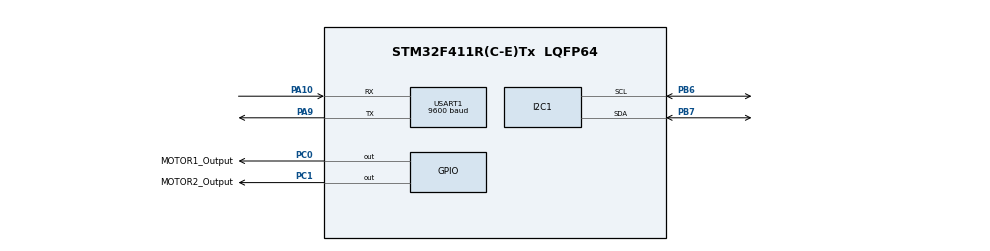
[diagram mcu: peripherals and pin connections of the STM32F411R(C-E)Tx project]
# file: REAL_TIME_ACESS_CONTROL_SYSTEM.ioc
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Mcu.Family=STM32F4
Mcu.Name=STM32F411R(C-E)Tx
Mcu.Package=LQFP64
NVIC.PriorityGroup=NVIC_PRIORITYGROUP_4
NVIC.RTC_Alarm_IRQn=true\:0\:0\:false\:false\:true\:true\:true\:true
NVIC.USART1_IRQn=true\:0\:0\:false\:false\:true\:true\:true\:true
PA10.Mode=Asynchronous
PA10.Signal=USART1_RX
PA9.Mode=Asynchronous
PA9.Signal=USART1_TX
PB6.Mode=I2C
PB6.Signal=I2C1_SCL
PB7.Mode=I2C
PB7.Signal=I2C1_SDA
PC0.GPIO_Label=MOTOR1_Output
PC0.Signal=GPIO_Output
PC1.GPIO_Label=MOTOR2_Output
PC1.Signal=GPIO_Output
ProjectManager.HeapSize=0x200
ProjectManager.StackSize=0x400
ProjectManager.TargetToolchain=STM32CubeIDE
RCC.AHBFreq_Value=16000000
RCC.APB1Freq_Value=16000000
RCC.APB2Freq_Value=16000000
RCC.CortexFreq_Value=16000000
RCC.HSE_VALUE=25000000
RCC.HSI_VALUE=16000000
RCC.LSE_VALUE=32768
RCC.SYSCLKFreq_VALUE=16000000
RCC.VCOOutputFreq_Value=192000000
RTC.Alarm=RTC_ALARM_A
RTC.Date=27
RTC.Format=RTC_FORMAT_BIN
RTC.Hours=9
RTC.Minutes=59
RTC.Month=RTC_MONTH_DECEMBER
RTC.Seconds=45
RTC.Seconds_A=10
RTC.WeekDay=RTC_WEEKDAY_TUESDAY
RTC.Year=22
USART1.BaudRate=9600
USART1.VirtualMode=VM_ASYNC
VP_RTC_VS_RTC_Activate.Mode=RTC_Enabled
VP_RTC_VS_RTC_Alarm_A_Intern.Mode=Alarm A
VP_RTC_VS_RTC_Calendar.Mode=RTC_Calendar
board=custom

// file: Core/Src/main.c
/* USER CODE BEGIN Header */
/**
  **********
  * @file           : main.c
  * @brief          : Main program body
  **********
  * @attention
  *
  * Copyright (c) 2022 STMicroelectronics.
  * All rights reserved.
  *
  * This software is licensed under terms that can be found in the LICENSE file
  * in the root directory of this software component.
  * If no LICENSE file comes with this software, it is provided AS-IS.
  *
  **********
  */
/* USER CODE END Header */
#include<stdio.h>
#include "main.h"
#include<string.h>
#include"lcd.h"
#include"RTC.h"

I2C_HandleTypeDef hi2c1;

RTC_HandleTypeDef hrtc;

UART_HandleTypeDef huart1;

RTC_HandleTypeDef hrtc;
RTC_TimeTypeDef sTime;
RTC_DateTypeDef sDate;
/* USER CODE BEGIN PV */
void MOTOR_Init(void);
void Rfid_Init(void);
/* USER CODE END PV */

void SystemClock_Config(void);
static void MX_GPIO_Init(void);
static void MX_I2C1_Init(void);
static void MX_RTC_Init(void);
static void MX_USART1_UART_Init(void);
/* USER CODE BEGIN PFP */
#define TRUE 1
#define FALSE 0
/* USER CODE END PFP */

/* USER CODE BEGIN 0 */
char *USER_DATA="Sankalp!";
uint8_t recvd_data;
	uint8_t data_buf[50];
	uint8_t count=0;
	uint8_t rec_comp_data=FALSE;
	char str[20];
	char *buffer[15];
/* USER CODE END 0 */

int main(void)
{

  /* MCU Configuration--------------------------------------------------------*/

  /* Reset of all peripherals, Initializes the Flash interface and the Systick. */
  HAL_Init();
  LCD_init();
//  RTC_init();

  /* Configure the system clock */
  SystemClock_Config();

  /* Initialize all configured peripherals */
  MX_GPIO_Init();
  MX_I2C1_Init();
  MX_RTC_Init();
  MX_USART1_UART_Init();
  /* USER CODE BEGIN 2 */
  Rfid_Init();

  /* USER CODE END 2 */

}

void Rfid_Init()
{
	LCD_command(1);
	  uint16_t len_of_data=strlen(USER_DATA);
	   HAL_UART_Transmit(&huart1, (uint8_t*)USER_DATA,len_of_data, HAL_MAX_DELAY);
	   while(rec_comp_data != TRUE)
	   {
	 	  HAL_UART_Receive_IT(&huart1,&recvd_data,1);
	   }
	   MOTOR_Init();
	   while(1);
	   return 0;
}

void HAL_UART_RxCpltCallback(UART_HandleTypeDef *huart)
{
	data_buf[count++]=recvd_data;
//	if(strcmp(data_buf,"18")==0)
//	{
//		LCD_command(1);
//		LCD_string("WELCOME ON BOARD");
//		LCD_command(0xC4);
//		LCD_string("SANKALP!");
//		LCD_command(1);
//		LCD_string("LOGIN TIME");
//		LCD_command(0xC4);
//		LCD_string(buffer1);
//		strcpy(data_buf,"/0");
//		MOTOR_Init();
//	}
//	else if(strcmp(data_buf,"3E")==0)
//	{
//		LCD_command(1);
//		LCD_string("WELCOME ON BOARD");
//		LCD_command(0xC4);
//		LCD_string("NARESH!");
//		LCD_command(1);
//		LCD_string("LOGIN TIME");
//		LCD_command(0xC4);
//		LCD_string(buffer1);
//		MOTOR_Init();
//	}
//	else if(strcmp(data_buf,"55")==0)
//	{
//		LCD_command(1);
//		LCD_string("WELCOME ON BOARD");
//		LCD_command(0xC4);
//		LCD_string("SANDEEP!");
//		LCD_command(1);
//		LCD_string("LOGIN TIME");
//		LCD_command(0xC4);
//		LCD_string(buffer1);
//		MOTOR_Init();
//	}
}

void MOTOR_Init()
{
	LCD_string(data_buf);
	HAL_Delay(100);
	strcpy(data_buf,'_');
	LCD_string(data_buf);
//	HAL_GPIO_WritePin(GPIOC, GPIO_PIN_0, 1);       //For Gate Open
//	HAL_GPIO_WritePin(GPIOC, GPIO_PIN_1, 0);
//	delay(3000);
//	HAL_GPIO_WritePin(GPIOC, GPIO_PIN_0, 0);        //Stop
//	HAL_GPIO_WritePin(GPIOC, GPIO_PIN_1, 0);
//	delay(2000);
//	HAL_GPIO_WritePin(GPIOC, GPIO_PIN_0, 0);       //For Gate Close
//	HAL_GPIO_WritePin(GPIOC, GPIO_PIN_1, 1);
//	delay(3000);
//	HAL_GPIO_WritePin(GPIOC, GPIO_PIN_0, 0);        //Stop
//	HAL_GPIO_WritePin(GPIOC, GPIO_PIN_1, 0);
//	Rfid_Init();
}

static void MX_USART1_UART_Init(void)
{

  huart1.Instance = USART1;
  huart1.Init.BaudRate = 9600;
  huart1.Init.WordLength = UART_WORDLENGTH_8B;
  huart1.Init.StopBits = UART_STOPBITS_1;
  huart1.Init.Parity = UART_PARITY_NONE;
  huart1.Init.Mode = UART_MODE_TX_RX;
  huart1.Init.HwFlowCtl = UART_HWCONTROL_NONE;
  huart1.Init.OverSampling = UART_OVERSAMPLING_16;
  if (HAL_UART_Init(&huart1) != HAL_OK)
  {
    Error_Handler();
  }

}

static void MX_GPIO_Init(void)
{
  GPIO_InitTypeDef GPIO_InitStruct = {0};

  /* GPIO Ports Clock Enable */
  __HAL_RCC_GPIOC_CLK_ENABLE();
  __HAL_RCC_GPIOA_CLK_ENABLE();
  __HAL_RCC_GPIOB_CLK_ENABLE();

  /*Configure GPIO pin Output Level */
  HAL_GPIO_WritePin(GPIOC, MOTOR1_Output_Pin|MOTOR2_Output_Pin, GPIO_PIN_RESET);

  /*Configure GPIO pins : MOTOR1_Output_Pin MOTOR2_Output_Pin */
  GPIO_InitStruct.Pin = MOTOR1_Output_Pin|MOTOR2_Output_Pin;
  GPIO_InitStruct.Mode = GPIO_MODE_OUTPUT_PP;
  GPIO_InitStruct.Pull = GPIO_NOPULL;
  GPIO_InitStruct.Speed = GPIO_SPEED_FREQ_LOW;
  HAL_GPIO_Init(GPIOC, &GPIO_InitStruct);

}

void Error_Handler(void)
{
  __disable_irq();
  while (1)
  {
  }
}
